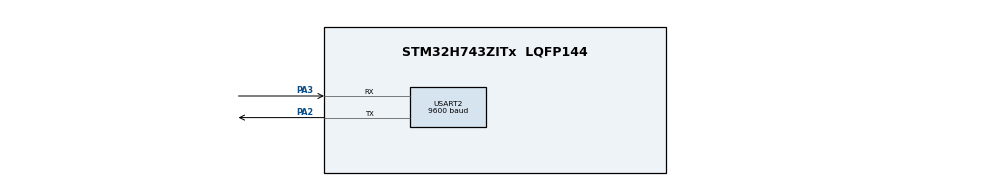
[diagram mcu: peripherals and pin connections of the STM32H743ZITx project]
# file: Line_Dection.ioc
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Mcu.Family=STM32H7
Mcu.Name=STM32H743ZITx
Mcu.Package=LQFP144
NVIC.PriorityGroup=NVIC_PRIORITYGROUP_4
NVIC.USART2_IRQn=true\:0\:0\:false\:false\:true\:true\:true
PA2.Mode=Asynchronous
PA2.Signal=USART2_TX
PA3.Mode=Asynchronous
PA3.Signal=USART2_RX
ProjectManager.HeapSize=0x200
ProjectManager.StackSize=0x400
ProjectManager.TargetToolchain=STM32CubeIDE
RCC.ADCFreq_Value=129000000
RCC.APB1Freq_Value=64000000
RCC.APB2Freq_Value=64000000
RCC.APB3Freq_Value=64000000
RCC.APB4Freq_Value=64000000
RCC.CortexFreq_Value=64000000
RCC.HCLKFreq_Value=64000000
RCC.SYSCLKFreq_VALUE=64000000
RCC.USBFreq_Value=129000000
TIM2.Period=99
TIM2.Prescaler=7999
USART2.BaudRate=9600
USART2.VirtualMode-Asynchronous=VM_ASYNC
VP_TIM2_VS_ClockSourceINT.Mode=Internal
board=custom

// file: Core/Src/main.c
/* USER CODE BEGIN Header */
/**
  ******************************************************************************
  * @file           : main.c
  * @brief          : Main program body
  ******************************************************************************
  * @attention
  *
  * <h2><center>&copy; Copyright (c) 2022 STMicroelectronics.
  * All rights reserved.</center></h2>
  *
  * This software component is licensed by ST under BSD 3-Clause license,
  * the "License"; You may not use this file except in compliance with the
  * License. You may obtain a copy of the License at:
  *                        opensource.org/licenses/BSD-3-Clause
  *
  ******************************************************************************
  */
/* USER CODE END Header */
#include "main.h"
#include "Line_Dection.h"
#include "UART_Data.h"
#include "Flash_Page.h"

TIM_HandleTypeDef htim2;

UART_HandleTypeDef huart2;

void SystemClock_Config(void);
static void MX_GPIO_Init(void);
static void MX_USART2_UART_Init(void);
static void MX_TIM2_Init(void);

int Vote_Matrix[a][2*r+1];
int Line_Matrix[height][width];
int main(void)
{

  /* MCU Configuration--------------------------------------------------------*/

  /* Reset of all peripherals, Initializes the Flash interface and the Systick. */
  HAL_Init();

  /* Configure the system clock */
  SystemClock_Config();

  /* Initialize all configured peripherals */
  MX_GPIO_Init();
  MX_USART2_UART_Init();
  MX_TIM2_Init();

  /* USER CODE BEGIN 2 */
  HAL_TIM_Base_Start_IT (& htim2 ) ;
  /* USER CODE END 2 */

  /* Infinite loop */
  /* USER CODE BEGIN WHILE */
  // Create Matrix
  Create_VoteTable();
  Create_LineMatrix();
  // Hough Space
  HoughTransform();
  // Get Line output and save in Image_Matrix
  Get_ImageLine();
  // UART Line
  UART_data();
  while (1)
  {
    /* USER CODE END WHILE */

  }
}

void SystemClock_Config(void)
{
  RCC_OscInitTypeDef RCC_OscInitStruct = {0};
  RCC_ClkInitTypeDef RCC_ClkInitStruct = {0};

  /** Supply configuration update enable
  */
  HAL_PWREx_ConfigSupply(PWR_LDO_SUPPLY);
  /** Configure the main internal regulator output voltage
  */
  __HAL_PWR_VOLTAGESCALING_CONFIG(PWR_REGULATOR_VOLTAGE_SCALE3);

  while(!__HAL_PWR_GET_FLAG(PWR_FLAG_VOSRDY)) {}
  /** Initializes the RCC Oscillators according to the specified parameters
  * in the RCC_OscInitTypeDef structure.
  */
  RCC_OscInitStruct.OscillatorType = RCC_OSCILLATORTYPE_HSI;
  RCC_OscInitStruct.HSIState = RCC_HSI_DIV1;
  RCC_OscInitStruct.HSICalibrationValue = RCC_HSICALIBRATION_DEFAULT;
  RCC_OscInitStruct.PLL.PLLState = RCC_PLL_NONE;
  if (HAL_RCC_OscConfig(&RCC_OscInitStruct) != HAL_OK)
  {
    Error_Handler();
  }
  /** Initializes the CPU, AHB and APB buses clocks
  */
  RCC_ClkInitStruct.ClockType = RCC_CLOCKTYPE_HCLK|RCC_CLOCKTYPE_SYSCLK
                              |RCC_CLOCKTYPE_PCLK1|RCC_CLOCKTYPE_PCLK2
                              |RCC_CLOCKTYPE_D3PCLK1|RCC_CLOCKTYPE_D1PCLK1;
  RCC_ClkInitStruct.SYSCLKSource = RCC_SYSCLKSOURCE_HSI;
  RCC_ClkInitStruct.SYSCLKDivider = RCC_SYSCLK_DIV1;
  RCC_ClkInitStruct.AHBCLKDivider = RCC_HCLK_DIV1;
  RCC_ClkInitStruct.APB3CLKDivider = RCC_APB3_DIV1;
  RCC_ClkInitStruct.APB1CLKDivider = RCC_APB1_DIV1;
  RCC_ClkInitStruct.APB2CLKDivider = RCC_APB2_DIV1;
  RCC_ClkInitStruct.APB4CLKDivider = RCC_APB4_DIV1;

  if (HAL_RCC_ClockConfig(&RCC_ClkInitStruct, FLASH_LATENCY_1) != HAL_OK)
  {
    Error_Handler();
  }
}

static void MX_TIM2_Init(void)
{

  TIM_ClockConfigTypeDef sClockSourceConfig = {0};
  TIM_MasterConfigTypeDef sMasterConfig = {0};

  htim2.Instance = TIM2;
  htim2.Init.Prescaler = 7999;
  htim2.Init.CounterMode = TIM_COUNTERMODE_UP;
  htim2.Init.Period = 99;
  htim2.Init.ClockDivision = TIM_CLOCKDIVISION_DIV1;
  htim2.Init.AutoReloadPreload = TIM_AUTORELOAD_PRELOAD_DISABLE;
  if (HAL_TIM_Base_Init(&htim2) != HAL_OK)
  {
    Error_Handler();
  }
  sClockSourceConfig.ClockSource = TIM_CLOCKSOURCE_INTERNAL;
  if (HAL_TIM_ConfigClockSource(&htim2, &sClockSourceConfig) != HAL_OK)
  {
    Error_Handler();
  }
  sMasterConfig.MasterOutputTrigger = TIM_TRGO_RESET;
  sMasterConfig.MasterSlaveMode = TIM_MASTERSLAVEMODE_DISABLE;
  if (HAL_TIMEx_MasterConfigSynchronization(&htim2, &sMasterConfig) != HAL_OK)
  {
    Error_Handler();
  }

}

static void MX_USART2_UART_Init(void)
{

  huart2.Instance = USART2;
  huart2.Init.BaudRate = 9600;
  huart2.Init.WordLength = UART_WORDLENGTH_8B;
  huart2.Init.StopBits = UART_STOPBITS_1;
  huart2.Init.Parity = UART_PARITY_NONE;
  huart2.Init.Mode = UART_MODE_TX_RX;
  huart2.Init.HwFlowCtl = UART_HWCONTROL_NONE;
  huart2.Init.OverSampling = UART_OVERSAMPLING_16;
  huart2.Init.OneBitSampling = UART_ONE_BIT_SAMPLE_DISABLE;
  huart2.Init.ClockPrescaler = UART_PRESCALER_DIV1;
  huart2.AdvancedInit.AdvFeatureInit = UART_ADVFEATURE_NO_INIT;
  if (HAL_UART_Init(&huart2) != HAL_OK)
  {
    Error_Handler();
  }
  if (HAL_UARTEx_SetTxFifoThreshold(&huart2, UART_TXFIFO_THRESHOLD_1_8) != HAL_OK)
  {
    Error_Handler();
  }
  if (HAL_UARTEx_SetRxFifoThreshold(&huart2, UART_RXFIFO_THRESHOLD_1_8) != HAL_OK)
  {
    Error_Handler();
  }
  if (HAL_UARTEx_DisableFifoMode(&huart2) != HAL_OK)
  {
    Error_Handler();
  }

}

static void MX_GPIO_Init(void)
{

  /* GPIO Ports Clock Enable */
  __HAL_RCC_GPIOA_CLK_ENABLE();

}

/* USER CODE BEGIN 4 */
int Time_Counter = 0;
void HAL_TIM_PeriodElapsedCallback ( TIM_HandleTypeDef * htim ){
	if(timer_flag == 1){
		Time_Counter++;
	}
	else{
		Time_Counter = Time_Counter;
	}
}
/* USER CODE END 4 */

void Error_Handler(void)
{
  __disable_irq();
  while (1)
  {
  }
}

/************************ (C) COPYRIGHT STMicroelectronics *****END OF FILE****/
